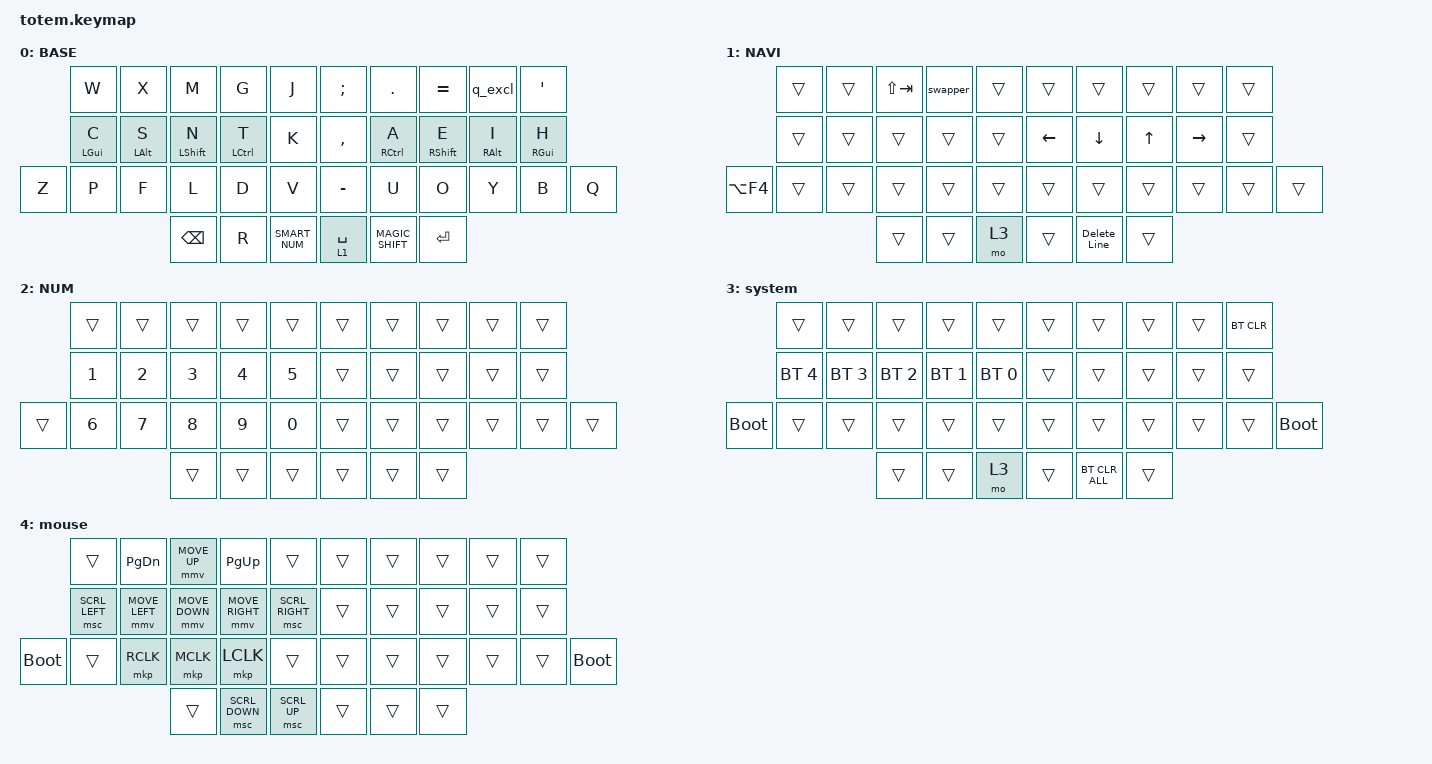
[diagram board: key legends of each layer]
// Mouse Movement
#define ZMK_POINTING_DEFAULT_MOVE_VAL 1500  // default: 600
#define ZMK_POINTING_DEFAULT_SCRL_VAL 20    // default: 10

#define BASE  0
#define NAV   1
#define NUM   2
#define SYM   3
#define MOUSE 4

// mouse definitions
#define MS_UP    &mmv MOVE_UP
#define MS_LEFT  &mmv MOVE_LEFT
#define MS_RIGHT &mmv MOVE_RIGHT
#define MS_DOWN  &mmv MOVE_DOWN
// scroll
#define MS_SCRL  &msc SCRL_LEFT
#define MS_SCRR  &msc SCRL_RIGHT
#define MS_SCRU  &msc SCRL_UP
#define MS_SCRD  &msc SCRL_DOWN




#include <behaviors.dtsi>
#include <dt-bindings/zmk/bt.h>
#include <dt-bindings/zmk/keys.h>

#include <dt-bindings/zmk/pointing.h>
#include "includes/mod.dtsi"
#include "includes/combos.dtsi"
#include "includes/smartnum.dtsi"
#include "includes/tristate.dtsi"
#include "includes/adaptivekey.dtsi"

&lt {
    flavor= "balanced";
    tapping-term-ms=<200>;
    quick-tap-ms=<175>;
};

/ {
    macros {

        Delete_Line: Delete_Line {
            compatible = "zmk,behavior-macro";
            #binding-cells = <0>;
            bindings = <&kp LC(A)>, <&macro_wait_time 20>, <&kp BSPC>;

            label = "DELETE_LINE";
        };
    };


    keymap {
        compatible = "zmk,keymap";

        base_layer {
            label = "BASE";
            bindings = <
               //╭──────────────┬──────────────┬──────────────┬──────────────┬──────────────╮╭──────────────┬──────────────┬──────────────┬──────────────┬──────────────╮
                   &kp W          &kp X          &kp M          &kp G          &kp J           &kp SEMI       &kp DOT        &kp EQUAL      &q_excl        &kp SQT
               //├──────────────┼──────────────┼──────────────┼──────────────┼──────────────┤├──────────────┼──────────────┼──────────────┼──────────────┼──────────────┤  
                   &hml LGUI C    &hml LALT S    &hml LSHFT N   &hml LCTRL T   &kp K           &kp COMMA      &hmr RCTRL A   &hmr RSHFT E   &hmr RALT I    &hmr RGUI H
//╭──────────────┼──────────────┼──────────────┼──────────────┼──────────────┼──────────────┤├──────────────┼──────────────┼──────────────┼──────────────┼──────────────┼──────────────╮ 
    &kp Z          &kp P          &kp F          &kp L          &kp D          &kp V           &kp MINUS      &kp U          &kp O          &kp Y          &kp B          &kp Q
//╰──────────────┴──────────────┴──────────────┼──────────────┼──────────────┼──────────────┤├──────────────┼──────────────┼──────────────┼──────────────┴──────────────┴──────────────╯
                                                 &kp BSPC       &kp R          SMART_NUM       &lt 1 SPACE    MAGIC_SHIFT    &kp ENTER      
//                                             ╰──────────────┴──────────────┴──────────────╯╰──────────────┴──────────────┴──────────────╯
            >;
        };

        nav {
            label = "NAVI";
            bindings = <
               //╭──────────────┬──────────────┬──────────────┬──────────────┬──────────────╮╭──────────────┬──────────────┬──────────────┬──────────────┬──────────────╮
                   &trans         &trans         &kp LS(TAB)     &swapper      &trans          &trans         &trans         &trans         &trans         &trans
               //├──────────────┼──────────────┼──────────────┼──────────────┼──────────────┤├──────────────┼──────────────┼──────────────┼──────────────┼──────────────┤  
                   &trans         &trans         &trans          &trans        &trans          &kp LEFT       &kp DOWN       &kp UP         &kp RIGHT      &trans
//╭──────────────┼──────────────┼──────────────┼──────────────┼──────────────┼──────────────┤├──────────────┼──────────────┼──────────────┼──────────────┼──────────────┼──────────────╮ 
   &kp LA(F4)      &trans         &trans         &trans          &trans        &trans          &trans         &trans         &trans         &trans         &trans         &trans
//╰──────────────┴──────────────┴──────────────┼──────────────┼──────────────┼──────────────┤├──────────────┼──────────────┼──────────────┼──────────────┴──────────────┴──────────────╯
                                                 &trans          &trans        &mo 3           &trans         &Delete_Line   &trans
//                                             ╰──────────────┴──────────────┴──────────────╯╰──────────────┴──────────────┴──────────────╯                                       
            >;
        };
        num {
            label = "NUM";
            bindings = <
               //╭──────────────┬──────────────┬──────────────┬──────────────┬──────────────╮╭──────────────┬──────────────┬──────────────┬──────────────┬──────────────╮
                   &trans         &trans         &trans          &trans        &trans          &trans         &trans         &trans         &trans         &trans
               //├──────────────┼──────────────┼──────────────┼──────────────┼──────────────┤├──────────────┼──────────────┼──────────────┼──────────────┼──────────────┤  
                   &kp N1         &kp N2         &kp N3          &kp N4        &kp N5          &trans         &trans         &trans         &trans         &trans
//╭──────────────┼──────────────┼──────────────┼──────────────┼──────────────┼──────────────┤├──────────────┼──────────────┼──────────────┼──────────────┼──────────────┼──────────────╮ 
   &trans          &kp N6         &kp N7         &kp N8          &kp N9        &kp N0          &trans         &trans         &trans         &trans         &trans         &trans
//╰──────────────┴──────────────┴──────────────┼──────────────┼──────────────┼──────────────┤├──────────────┼──────────────┼──────────────┼──────────────┴──────────────┴──────────────╯
                                                 &trans          &trans        &trans          &trans         &trans         &trans
//                                             ╰──────────────┴──────────────┴──────────────╯╰──────────────┴──────────────┴──────────────╯  
            >;
        };
        system {
            bindings = <
               //╭──────────────┬──────────────┬──────────────┬──────────────┬──────────────╮╭──────────────┬──────────────┬──────────────┬──────────────┬──────────────╮
                   &trans         &trans         &trans          &trans        &trans          &trans         &trans         &trans         &trans         &bt BT_CLR
               //├──────────────┼──────────────┼──────────────┼──────────────┼──────────────┤├──────────────┼──────────────┼──────────────┼──────────────┼──────────────┤  
                   &bt BT_SEL 4   &bt BT_SEL 3   &bt BT_SEL 2    &bt BT_SEL 1  &bt BT_SEL 0    &trans         &trans         &trans         &trans         &trans
//╭──────────────┼──────────────┼──────────────┼──────────────┼──────────────┼──────────────┤├──────────────┼──────────────┼──────────────┼──────────────┼──────────────┼──────────────╮ 
   &bootloader     &trans         &trans         &trans          &trans        &trans          &trans         &trans         &trans         &trans         &trans         &bootloader
//╰──────────────┴──────────────┴──────────────┼──────────────┼──────────────┼──────────────┤├──────────────┼──────────────┼──────────────┼──────────────┴──────────────┴──────────────╯
                                                 &trans          &trans        &mo 3           &trans         &bt BT_CLR_ALL &trans
//                                             ╰──────────────┴──────────────┴──────────────╯╰──────────────┴──────────────┴──────────────╯
            >;
        };
        mouse {
            bindings = <
               //╭──────────────┬──────────────┬──────────────┬──────────────┬──────────────╮╭──────────────┬──────────────┬──────────────┬──────────────┬──────────────╮
                   &trans         &kp PG_DN      MS_UP           &kp PG_UP     &trans          &trans         &trans         &trans         &trans         &trans
               //├──────────────┼──────────────┼──────────────┼──────────────┼──────────────┤├──────────────┼──────────────┼──────────────┼──────────────┼──────────────┤  
                   MS_SCRL        MS_LEFT        MS_DOWN         MS_RIGHT      MS_SCRR         &trans         &trans         &trans         &trans         &trans
//╭──────────────┼──────────────┼──────────────┼──────────────┼──────────────┼──────────────┤├──────────────┼──────────────┼──────────────┼──────────────┼──────────────┼──────────────╮ 
   &bootloader     &trans         &mkp RCLK      &mkp MCLK       &mkp LCLK     &trans          &trans         &trans         &trans         &trans         &trans         &bootloader
//╰──────────────┴──────────────┴──────────────┼──────────────┼──────────────┼──────────────┤├──────────────┼──────────────┼──────────────┼──────────────┴──────────────┴──────────────╯
                                                 &trans          MS_SCRD       MS_SCRU         &trans         &trans         &trans
//                                             ╰──────────────┴──────────────┴──────────────╯╰──────────────┴──────────────┴──────────────╯
            >;
        };

// ▄▄▄▄▄▄▄▄▄▄▄▄▄▄▄▄▄▄▄▄▄▄▄▄▄▄▄▄▄▄▄▄▄▄▄▄▄▄▄▄▄▄▄▄▄▄▄▄▄▄▄▄▄▄▄▄▄▄▄▄▄▄▄▄▄▄▄▄▄▄▄▄▄▄▄▄▄▄▄▄▄▄▄▄▄▄▄▄▄▄▄▄▄▄▄▄▄▄▄▄▄▄▄▄▄▄▄▄▄▄▄▄▄▄▄▄▄▄▄▄▄▄▄▄▄▄▄▄▄▄▄▄▄▄▄▄▄▄▄▄▄▄▄▄▄▄▄▄▄▄▄▄▄▄▄▄▄▄▄▄▄▄▄▄▄▄▄▄▄▄▄▄▄▄▄▄▄▄▄▄▄▄▄▄▄▄▄▄▄▄▄▄▄     
    };
};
